# PCIE_0_PHY_CFG register map
Vendor: Texas Instruments
Peripheral module from a debugger description file (folder 66AK2G0x_66AK2G1x).
Registers are 32-bit, access per field, reset 0x0 unless marked. A register's access mark holds for its fields unless they carry their own. Offsets are as the file gives them; lines under a group give offsets from that group; [hi:lo] are bit positions; {n}, {i} and the like mark numbered series; 'fields as' and 'values as' point back to an identical list; <NAME> marks a mode.

## PCIE_0_PHY_CFG
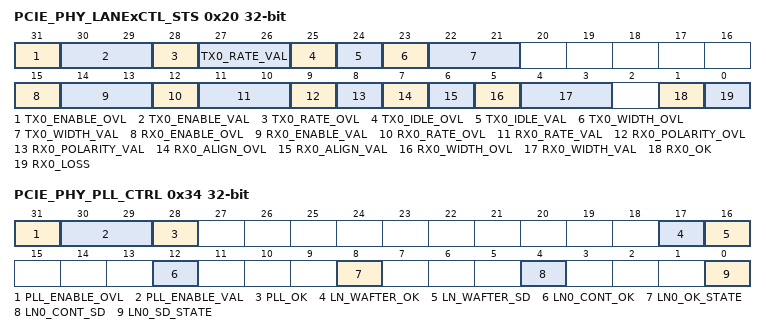
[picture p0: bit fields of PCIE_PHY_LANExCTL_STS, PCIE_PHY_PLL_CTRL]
0x20 PCIE_PHY_LANExCTL_STS (reset mask 0xFFFFFFFE)
  [31] TX0_ENABLE_OVL rw — The Tx Enable Overlay bit when set allows the Tx Enable Value to override the CFGTX Enable input.
  [30:29] TX0_ENABLE_VAL rw — The Tx Enable Value when used allows the Tx lane to be placed in
  [28] TX0_RATE_OVL rw — The Tx Rate Overlay bit when set allows the Tx Rate Value to override the CFGTX Rate input.
  [27:26] TX0_RATE_VAL rw — The Tx Rate Value when used allows the Tx lane to be placed into:
  [25] TX0_IDLE_OVL rw — The Tx Idle Overlay bit when set allows the Tx Idle Value to override the CFGTX.Idle input.
  [24] TX0_IDLE_VAL rw — The Tx Idle Value when used allows the Tx lane to be placed electrical Idle state in non PCIE mode.
  [23] TX0_WIDTH_OVL rw — The Tx Width Overlay bit when set allows the Tx Width Value to override the CFGTX.Width input.
  [22:21] TX0_WIDTH_VAL rw — The Tx Width Value when used allows the Tx lane to be placed into:
  [15] RX0_ENABLE_OVL rw — The Rx Enable Overlay bit when set allows the Rx Enable Value to override the CFGRX Enable input.
  [14:13] RX0_ENABLE_VAL rw — The Rx Enable Value when used allows the Rx lane to be placed in:
  [12] RX0_RATE_OVL rw — The Rx Rate Overlay bit when set allows the Rx Rate Value to override the CFGRX Rate input.
  [11:10] RX0_RATE_VAL rw — The Rx Rate Value when used allows the Rx lane to be placed into:
  [9] RX0_POLARITY_OVL rw — The Rx Polarity Overlay bit when set allows the Rx Polarity Value to override the CFGRX.Polarity input.
  [8] RX0_POLARITY_VAL rw — The Rx Polarity Value when used allows the lane Rx Polarity to be inverted.
  [7] RX0_ALIGN_OVL rw — The Rx Align Overlay bit when set allows the Rx Align Value to override the CFGRX.Align input.
  [6] RX0_ALIGN_VAL rw — The Rx Align Value when used allows the Rx lane to align to K28.1, K28.5 and K28.7 characters otherwise known as Comma Characters.
  [5] RX0_WIDTH_OVL rw — The Rx Width Overlay bit when set allows the Rx Width Value to override the CFGRX Width input.
  [4:3] RX0_WIDTH_VAL rw — The Rx Width Value when used allows the Rx lane to be placed into
  [1] RX0_OK ro — The Rx OK indicate that the lane is in a functional state.
  [0] RX0_LOSS ro — The Rx Signal Loss Indicates that the data has not been detected or the CDR is not locked.
0x34 PCIE_PHY_PLL_CTRL
  [31] PLL_ENABLE_OVL rw — The PLL Enable Overlay bit when set allows the PLL Enable Value to override the CFGPLL.Enable input.
  [30:29] PLL_ENABLE_VAL rw — The PLL Enable Value when used allows the PLL to be placed in
  [28] PLL_OK ro — The PLL Ok indicate that the transmit clocks are valid and the PLL circuits are ready for use.
  [17] LN_WAFTER_OK rw — The LN_WAFTER_OK field will cause the lane OK indication to be Blocked until the LNX_CONT_OK is set. This allows code to run after the lane OK but before the hardware can use the lane.
  [16] LN_WAFTER_SD rw — The LN_WAFTER_SD field will cause the Rx signal indication to be Blocked until the LNX_CONT_SD is set. This allows code to run after signal detect but before the hardware can use the data.
  [12] LN0_CONT_OK rw — The LN0_CONT_OK allows the Blocked lane OK for lane 0 to now pass to the controlling PCS IP. This bit is auto cleared when LN0_OK_STATE is driven inactive.
  [8] LN0_OK_STATE ro — The LN0_OK_STATE indicate the current state of the lane OK signal for lane 0.
  [4] LN0_CONT_SD rw — The LN0_CONT_SD allows the Blocked signal detect for lane 0 to now pass to the controlling PCS IP. This bit is auto cleared when LN0_SD_STATE is driven inactive.
  [0] LN0_SD_STATE ro — The LN0_SD_STATE indicate the current state of the signal detect signal for lane 0.
0x38 PCIE_PHY_COMMA_LINK_DELAY ro
  [7:0] LANE0_CDELAY — Defines the number of network bits the comma aligner has added to the fixed delay of the PCS/PMA layer for lane 0.
0x3C PCIE_PHY_CMU_WAIT ro
  [16:0] WAIT_VAL — Defines the number of clock cycles between writing to the CMU Reset register and CMU_RESET_I activation.
